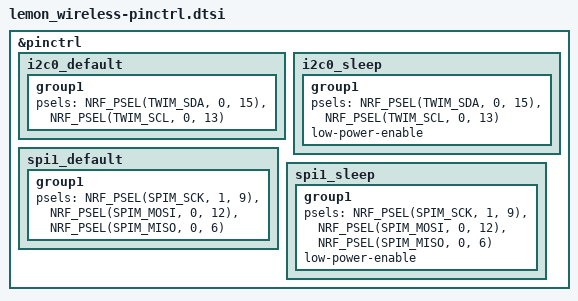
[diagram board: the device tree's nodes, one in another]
/*
 * Copyright (c) 2022 The ZMK Contributors
 * SPDX-License-Identifier: MIT
 */

&pinctrl {
    i2c0_default: i2c0_default {
        group1 {
            psels = <NRF_PSEL(TWIM_SDA, 0, 15)>,
                <NRF_PSEL(TWIM_SCL, 0, 13)>;
        };
    };

    i2c0_sleep: i2c0_sleep {
        group1 {
            psels = <NRF_PSEL(TWIM_SDA, 0, 15)>,
                <NRF_PSEL(TWIM_SCL, 0, 13)>;
            low-power-enable;
        };
    };

    spi1_default: spi1_default {
        group1 {
            psels = <NRF_PSEL(SPIM_SCK, 1, 9)>,
                <NRF_PSEL(SPIM_MOSI, 0, 12)>,
                <NRF_PSEL(SPIM_MISO, 0, 6)>;
        };
    };

    spi1_sleep: spi1_sleep {
        group1 {
            psels = <NRF_PSEL(SPIM_SCK, 1, 9)>,
                <NRF_PSEL(SPIM_MOSI, 0, 12)>,
                <NRF_PSEL(SPIM_MISO, 0, 6)>;
            low-power-enable;
        };
    };
};
